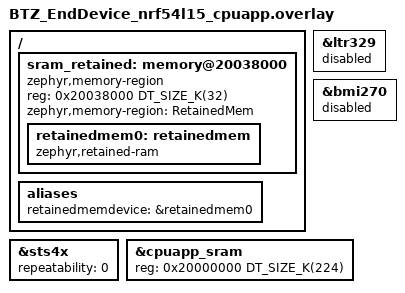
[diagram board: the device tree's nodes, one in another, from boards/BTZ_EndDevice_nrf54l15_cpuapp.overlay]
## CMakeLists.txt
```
cmake_minimum_required(VERSION 3.20.0)

find_package(Zephyr REQUIRED HINTS $ENV{ZEPHYR_BASE})
project(lpn_off)

target_sources(app PRIVATE
  src/main.c
  src/model_handler.c
  src/retained.c
)

zephyr_library_include_directories(.)
# net.h stosu mesh - stad bt_mesh.seq, ktore odtwarzamy po System OFF
zephyr_library_include_directories(${ZEPHYR_BASE}/subsys/bluetooth/mesh)
```

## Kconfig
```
# Parametry aplikacji LPN OFF sterowane flaga builda (-DCONFIG_...=...).
# Nazwy zgodne z apps/lpn i apps/lpn_mock - ta sama flaga dziala we wszystkich.

config LPN_SENSOR_INTERVAL_S
	int "Interwal odczytu i publikacji temperatury do Frienda [s]"
	default 10
	range 1 86400
	help
	  Odstep miedzy kolejnymi publikacjami Sensor Server -> Friend.
	  Sterowane build-time: -DCONFIG_LPN_SENSOR_INTERVAL_S=<sekundy>.

	  Tu jest to jednoczesnie czas spedzony w System OFF: wezel budzi sie,
	  publikuje i znowu odcina zasilanie. Pobudke daje GRTC taktowany z LFXO.

config LPN_PROV_TIMEOUT_S
	int "Limit czasu na provisioning i konfiguracje od Frienda [s]"
	default 60
	range 5 600
	help
	  Dotyczy tylko zimnego startu. Po przekroczeniu wezel i tak idzie w
	  System OFF, zeby pomiar nie zawisl.

config LPN_CFG_SETTLE_MS
	int "Zapas po wykryciu konca konfiguracji, przed wejsciem w tryb LPN [ms]"
	default 8000
	range 0 30000
	help
	  Dotyczy tylko zimnego startu. Znacznikiem konca konfiguracji jest
	  ustawiony adres publikacji, czyli ostatni krok Frienda (mod_pub_set) -
	  ten zapas pokrywa tylko retransmisje Frienda po zgubionym Status.

	  Caly ten czas LPN jest zwyklym wezlem mesh, wiec skanuje bez przerwy
	  (~4-5 mA). Do pomiarow energii warto zejsc do 500-1000 ms:
	  -DCONFIG_LPN_CFG_SETTLE_MS=1000.

config LPN_FRIENDSHIP
	bool "Nawiazuj friendship przed publikacja"
	default y
	help
	  Wylacz, zeby zmierzyc cykl bez kosztu Friend Request (okno na oferty
	  to ~1,1 s ciaglego RX). Publikacja dziala bez friendship - to tylko TX.

config LPN_FRIENDSHIP_TIMEOUT_S
	int "Limit czasu na nawiazanie friendship [s]"
	default 20
	range 1 120
	help
	  Bez "depends on LPN_FRIENDSHIP" swiadomie: main.c bramkuje uzycie
	  zwyklym if-em na IS_ENABLED(), a nie #if, wiec ten symbol musi istniec
	  takze przy LPN_FRIENDSHIP=n - inaczej build nie linkuje sie na
	  niezdefiniowanym CONFIG_LPN_FRIENDSHIP_TIMEOUT_S.

config LPN_DRAIN_MS
	int "Zwloka po publikacji, zeby reklama wyszla w eter [ms]"
	default 500
	range 0 5000
	help
	  System OFF ucina nadawanie w polowie, wiec trzeba dac adverowi czas.

config LPN_SEQ_MARGIN
	int "Zapas doliczany do odtworzonego licznika seq"
	default 32
	range 0 4096
	help
	  Pokrywa wiadomosci, ktore mogly wyjsc po zapisie bloku retencyjnego.
	  Bez zapasu Friend moglby odrzucic nas na replay protection.

source "Kconfig.zephyr"
```

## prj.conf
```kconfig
# Wariant do POMIARU ENERGII: pelny cykl LPN, potem System OFF z pobudka z GRTC.
# Czujnik REALNY (STS4X). Wersja z retencja RAM: -DEXTRA_CONF_FILE=overlay-ret.conf

# Logi i konsola: WYLACZONE (UART i watek logow pobieraja prad)
CONFIG_LOG=n
CONFIG_SERIAL=n
CONFIG_CONSOLE=n
CONFIG_UART_CONSOLE=n
# Board defconfig wymusza RTT_CONSOLE=y - gasimy jawnie (jak w apps/baseline).
CONFIG_RTT_CONSOLE=n
# Potrzebne tylko do drukowania floatow w logach (bt_mesh_sensor_ch_str).
CONFIG_CBPRINTF_FP_SUPPORT=n

# BLE
CONFIG_BT=y
CONFIG_BT_DEVICE_NAME="LPN Off"
CONFIG_BT_OBSERVER=y
CONFIG_BT_BROADCASTER=y

# Mesh: provisioning REALNY - adres i klucze przychodza od Frienda
CONFIG_BT_MESH=y
CONFIG_BT_MESH_PB_ADV=y

# Rola LPN
CONFIG_BT_MESH_LOW_POWER=y
# 600 x 100 ms = 60 s; ta sama wartosc co w apps/lpn, zeby pomiary byly porownywalne.
CONFIG_BT_MESH_LPN_POLL_TIMEOUT=600
CONFIG_BT_MESH_LPN_RETRY_TIMEOUT=3
# Opoznienie Friend Offer liczy Friend jako
# MAX(RECV_WIN_FACTOR * FRIEND_RECV_WIN - RSSI_FACTOR * rssi, 100) ms.
# Przy FRIEND_RECV_WIN=50 i faktorze 1.0 wychodzi ~100 ms, a LPN z
# LPN_ESTABLISHMENT=y ma w tym momencie scanner JESZCZE wylaczony
# (FRIEND_REQ_WAIT = 100 ms w lpn.c). Oferta leci jednym adverem, wiec
# przepada, a kolejna proba to 1,1 s okna + 3 s retry. Faktor 2.0 przesuwa
# oferte na ~140-160 ms, czyli w srodek okna skanowania LPN-a.
# Nie kosztuje energii: LPN i tak skanuje przez cale okno ofert.
CONFIG_BT_MESH_LPN_RECV_WIN_FACTOR=2
# ODWROTNIE niz w apps/lpn: tu friendship nawiazujemy w KAZDYM cyklu, wiec
# zredukowany duty cycle skanowania (domyslne =y) oplaca sie kilkukrotnie.
# Przy =n radio skanuje bez przerwy przez cale okno ofert i przez kazda 3 s przerwe retry.
CONFIG_BT_MESH_LPN_ESTABLISHMENT=y
# Auto-LPN OFF: w tryb LPN wchodzimy recznie, po konfiguracji (patrz main.c).
CONFIG_BT_MESH_LPN_AUTO=n

# Funkcje wymagajace ciagle wlaczonego radia - zbedne dla LPN
CONFIG_BT_MESH_RELAY=n
CONFIG_BT_MESH_FRIEND=n
CONFIG_BT_MESH_BEACON_ENABLED=n
CONFIG_BT_MESH_GATT_PROXY_ENABLED=n

# Sensor Server: jeden czujnik (temperatura z STS4X)
CONFIG_BT_MESH_SENSOR_SRV=y
CONFIG_BT_MESH_SENSOR_SRV_SENSORS_MAX=1

# Wezel BEZSTANOWY: po restarcie Friend prowizjonuje go od nowa
CONFIG_BT_SETTINGS=n
# Settings/flash zostaja: bez nich blad linkera storage_*_object (PSA ITS na nRF54L).
CONFIG_SETTINGS=y
CONFIG_FLASH=y
CONFIG_FLASH_MAP=y

# System OFF z pobudka z GRTC - GRTC leci z LFXO, wiec odlicza takze w OFF
CONFIG_POWEROFF=y
CONFIG_REBOOT=y
# Rozpoznanie, czy to zimny start czy pobudka z OFF (RESET_CLOCK)
CONFIG_HWINFO=y

# Blok retencyjny: sterownik jest w OBU wariantach, zeby mapa pamieci byla ta sama.
# Sama retencje w System OFF wlacza dopiero RETAINED_MEM_NRF_RAM_CTRL.
CONFIG_RETAINED_MEM=y
CONFIG_RETAINED_MEM_ZEPHYR_RAM=y
CONFIG_RETAINED_MEM_NRF_RAM_CTRL=n
CONFIG_CRC=y

# Stosy i bufory
CONFIG_MAIN_STACK_SIZE=4400
CONFIG_MAIN_THREAD_PRIORITY=-2
CONFIG_SYSTEM_WORKQUEUE_STACK_SIZE=4800
CONFIG_BT_MESH_RX_SEG_MAX=32
CONFIG_BT_MESH_TX_SEG_MSG_COUNT=3
# Wiecej buforow adv: wezel odbiera segmenty i jednoczesnie odsyla ACK.
CONFIG_BT_MESH_ADV_BUF_COUNT=16

# SAR RX: prog 1, bo AppKey Add ma 2 segmenty a ACK retransmituje sie gdy > prog
CONFIG_BT_MESH_SAR_RX_SEG_THRESHOLD=0x01
# ACK wysylany 4x - pojedynczy zgubiony ACK konczyl konfiguracje bledem -116.
CONFIG_BT_MESH_SAR_RX_ACK_RETRANS_COUNT=0x03
# Dluzszy discard: niekompletny SDU przezywa okno retransmisji Frienda.
CONFIG_BT_MESH_SAR_RX_DISCARD_TIMEOUT=0x0a
# NETWORK_TRANSMIT zostaje DOMYSLNY - podnoszenie go opoznialo ACK i zapychalo adv.

# --- Niezawodnosc provisioningu (PB-ADV) ---
# Domyslnie PDU danych provisioningu leca POJEDYNCZO (retrans=0) - tylko ACK i
# Link Close maja 2 powtorzenia. Na granicznym linku gubi sie ich dosc, ze
# wymiana nie domyka sie przed watchdogiem Frienda. 7 = kazde PDU nadane 8x.
CONFIG_BT_MESH_PB_ADV_TRANS_PDU_RETRANSMIT_COUNT=7
# Beacon nieprovisionowanego co 1 s zamiast co 5 s - Friend znajduje nas szybciej.
CONFIG_BT_MESH_UNPROV_BEACON_INT=1
# Pelna moc nadawania. Domyslne 0 dBm nie wyrabialo na 5 m.
CONFIG_BT_CTLR_TX_PWR_ANTENNA=8

# --- Opcjonalny lewar energetyczny (odkomentuj i zmierz) ---
# Publikacja idzie 1x zamiast 3x. Dotyczy tylko Sensor Status - Friend Request
# i Friend Poll i tak leca pojedynczo (POLL_XMIT w lpn.c).
#CONFIG_BT_MESH_NETWORK_TRANSMIT_COUNT=0
```

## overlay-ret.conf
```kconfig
# Wariant Z RETENCJA RAM: sekcja retencyjna przezywa System OFF.
# Jedyna roznica wobec prj.conf - reszta konfiguracji i mapa pamieci sa te same.
CONFIG_RETAINED_MEM_NRF_RAM_CTRL=y
```

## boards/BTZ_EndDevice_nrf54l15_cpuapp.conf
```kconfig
CONFIG_ZMS=y
CONFIG_SETTINGS_ZMS_CUSTOM_SECTOR_COUNT=y
CONFIG_SETTINGS_ZMS_SECTOR_COUNT=8
CONFIG_ZMS_LOOKUP_CACHE=y
CONFIG_ZMS_LOOKUP_CACHE_SIZE=512
CONFIG_ZMS_LOOKUP_CACHE_FOR_SETTINGS=y

CONFIG_I2C=y
CONFIG_REGULATOR=y
CONFIG_REGULATOR_FIXED=y
CONFIG_SENSOR=y
```

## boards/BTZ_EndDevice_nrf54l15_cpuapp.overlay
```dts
/*
 * Wylaczamy nieuzywane czujniki, zeby zdjac ten narzut energetyczny.
 */

&ltr329 {
	status = "disabled";
};

&bmi270 {
	status = "disabled";
};

/*
 * STS4X: tryb pomiaru "low"
 */
&sts4x {
	repeatability = <0>;
};

/*
 * Region retencyjny na ostatniej sekcji RAM. Granulacja retencji na nRF54L15
 * to 32 kB (RAM_SECTION_UNIT_SIZE), wiec mniejszy region i tak podtrzymalby
 * cala sekcje - trzymamy wiec pelne 32 kB, zeby koszt byl jawny.
 * Region jest w OBU wariantach builda; retencje wlacza dopiero Kconfig.
 */
/ {
	sram_retained: memory@20038000 {
		compatible = "zephyr,memory-region", "mmio-sram";
		reg = <0x20038000 DT_SIZE_K(32)>;
		zephyr,memory-region = "RetainedMem";
		status = "okay";

		retainedmem0: retainedmem {
			compatible = "zephyr,retained-ram";
			status = "okay";
		};
	};

	aliases {
		retainedmemdevice = &retainedmem0;
	};
};

/* SRAM skrocony do 224 kB, zeby nie nachodzil na region retencyjny */
&cpuapp_sram {
	reg = <0x20000000 DT_SIZE_K(224)>;
	ranges = <0x0 0x20000000 0x38000>;
};
```

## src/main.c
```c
#include <bluetooth/mesh/models.h>
#include <stdint.h>
#include <zephyr/bluetooth/bluetooth.h>
#include <zephyr/bluetooth/mesh.h>
#include <zephyr/drivers/hwinfo.h>
#include <zephyr/drivers/timer/nrf_grtc_timer.h>
#include <zephyr/kernel.h>
#include <zephyr/logging/log.h>
#include <zephyr/sys/poweroff.h>
#include <zephyr/sys/reboot.h>

#include "model_handler.h"
#include "retained.h"

/* Wewnetrzny stan sieci mesh - stad bierzemy i odtwarzamy licznik seq */
#include "net.h"

LOG_MODULE_REGISTER(lpn_off, LOG_LEVEL_INF);

/* Adresacja i klucze - musza zgadzac sie z apps/friend */
#define NET_IDX     0x0000
#define APP_IDX     0x0000
#define FRIEND_ADDR 0x0001

static const uint8_t net_key[16] = {
    0x00, 0x11, 0x22, 0x33, 0x44, 0x55, 0x66, 0x77, 0x88, 0x99, 0xaa, 0xbb, 0xcc, 0xdd, 0xee, 0xff,
};
static const uint8_t app_key[16] = {
    0xff, 0xee, 0xdd, 0xcc, 0xbb, 0xaa, 0x99, 0x88, 0x77, 0x66, 0x55, 0x44, 0x33, 0x22, 0x11, 0x00,
};
/* DevKey po cieplym starcie - Friend nie wysyla juz Configa, wiec moze byc staly */
static const uint8_t lpn_dev_key[16] = {
    0xb0, 0xb1, 0xb2, 0xb3, 0xb4, 0xb5, 0xb6, 0xb7, 0xb8, 0xb9, 0xba, 0xbb, 0xbc, 0xbd, 0xbe, 0xbf,
};

/* UUID w unprovisioned beacon - Friend provisionuje tylko ten wezel */
static const uint8_t dev_uuid[16] = {0x1b, 0x7a, 0x0c, 0x54};

/* Interwal publikacji temperatury - tu zarazem czas w System OFF (patrz Kconfig) */
#ifndef CONFIG_LPN_SENSOR_INTERVAL_S
#define CONFIG_LPN_SENSOR_INTERVAL_S 10
#endif

/* Co ile pytac, czy Friend domknal konfiguracje */
#define CFG_POLL_INTERVAL K_MSEC(200)
/* Zapas na retry Frienda po zgubionym Status (patrz Kconfig) */
#define CFG_SETTLE_DELAY K_MSEC(CONFIG_LPN_CFG_SETTLE_MS)

static K_SEM_DEFINE(sem_provisioned, 0, 1);
static K_SEM_DEFINE(sem_friendship, 0, 1);

/* Provisioning zakonczony - wezel ma adres i klucze, czekamy na konfiguracje */
static void prov_complete(uint16_t net_idx, uint16_t addr)
{
    LOG_INF("Sprovisionowany przez Frienda - adres 0x%04x", addr);

    retained.addr = addr;
    k_sem_give(&sem_provisioned);
}

static const struct bt_mesh_prov prov = {
    .uuid = dev_uuid,
    .complete = prov_complete,
};

/* Callbacki LPN */
static void lpn_established(uint16_t net_idx, uint16_t friend_addr, uint8_t queue_size,
                            uint8_t recv_window)
{
    LOG_INF("Friendship nawiazany z Friendem 0x%04x (queue %u, recv_window %u ms)", friend_addr,
            queue_size, recv_window);

    k_sem_give(&sem_friendship);
}

static void lpn_terminated(uint16_t net_idx, uint16_t friend_addr)
{
    LOG_WRN("Friendship zerwany z Friendem 0x%04x", friend_addr);
}

BT_MESH_LPN_CB_DEFINE(lpn_cb) = {
    .established = lpn_established,
    .terminated = lpn_terminated,
};

/* Odklada stan do retencji i odcina zasilanie; GRTC (z LFXO) budzi nas z OFF */
static void enter_system_off(void)
{
    /* seq musi rosnac monotonicznie, inaczej Friend odrzuci nas na replay protection */
    retained.iv_index = bt_mesh.iv_index;
    retained.seq = bt_mesh.seq;
    retained.cycles++;
    retained_save();

    int err = z_nrf_grtc_wakeup_prepare((uint64_t)CONFIG_LPN_SENSOR_INTERVAL_S * USEC_PER_SEC);

    if (err) {
        /* Bez uzbrojonej pobudki System OFF bylby wieczny - lepiej sie zrestartowac */
        LOG_ERR("Uzbrojenie pobudki GRTC nieudane (err %d) - restart", err);
        k_sleep(K_SECONDS(CONFIG_LPN_SENSOR_INTERVAL_S));
        sys_reboot(SYS_REBOOT_COLD);
    }

    LOG_INF("System OFF na %d s (cykl %u)", CONFIG_LPN_SENSOR_INTERVAL_S, retained.cycles);
    sys_poweroff();
}

/* Sciezka zimnego startu: pelny provisioning i konfiguracja od Frienda */
static int join_network_cold(void)
{
    int err = bt_mesh_prov_enable(BT_MESH_PROV_ADV);

    if (err) {
        LOG_ERR("Wlaczenie provisioningu (beacon) nieudane (err %d)", err);
        return err;
    }

    LOG_INF("Czekam na provisioning od Frienda...");
    err = k_sem_take(&sem_provisioned, K_SECONDS(CONFIG_LPN_PROV_TIMEOUT_S));
    if (err) {
        LOG_ERR("Provisioning nie doszedl do skutku w %d s", CONFIG_LPN_PROV_TIMEOUT_S);
        return err;
    }

    /* Adres publikacji ustawia ostatni krok konfiguracji - to nasz znacznik konca */
    for (int i = 0; i < CONFIG_LPN_PROV_TIMEOUT_S * 5; i++) {
        if (model_handler_is_configured()) {
            LOG_INF("Konfiguracja zakonczona (publikacja ustawiona)");
            k_sleep(CFG_SETTLE_DELAY);
            retained.provisioned = 1;
            return 0;
        }
        k_sleep(CFG_POLL_INTERVAL);
    }

    LOG_ERR("Friend nie domknal konfiguracji");
    return -ETIMEDOUT;
}

/* Sciezka cieplego startu: siec i konfiguracja odtworzone z retencji, bez radia */
static int join_network_warm(void)
{
    int err = bt_mesh_provision(net_key, NET_IDX, 0, retained.iv_index, retained.addr, lpn_dev_key);

    if (err) {
        LOG_ERR("Odtworzenie provisioningu nieudane (err %d)", err);
        return err;
    }

    /* Kontynuuj licznik seq z zapasem na cokolwiek, co wyszlo po ostatnim zapisie */
    bt_mesh.seq = retained.seq + CONFIG_LPN_SEQ_MARGIN;

    err = model_handler_restore_config(NET_IDX, APP_IDX, app_key, FRIEND_ADDR);
    if (err) {
        return err;
    }

    LOG_INF("Siec odtworzona z retencji - adres 0x%04x, seq %u", retained.addr, bt_mesh.seq);
    return 0;
}

int main(void)
{
    uint32_t reset_cause = 0;
    int err;

    (void)hwinfo_get_reset_cause(&reset_cause);
    (void)hwinfo_clear_reset_cause();

    /* Waznosc bloku retencyjnego rozstrzyga, ktora sciezka startu nas czeka */
    bool warm = retained_load();

    LOG_INF("Start lpn_off: %s (cykl %u, reset 0x%08x)",
            warm ? "cieply start z retencji RAM" : "zimny start", retained.cycles, reset_cause);

    err = bt_enable(NULL);
    if (err) {
        LOG_ERR("bt_enable nieudany (err %d)", err);
        enter_system_off();
    }

    err = bt_mesh_init(&prov, model_handler_init());
    if (err) {
        LOG_ERR("Inicjalizacja mesh nieudana (err %d)", err);
        enter_system_off();
    }

    if (warm && retained.provisioned) {
        err = join_network_warm();
    }
    else {
        err = join_network_cold();
    }

    if (err) {
        /* Nie udalo sie wejsc do sieci - i tak zasnij, zeby pomiar szedl dalej */
        enter_system_off();
    }

    if (IS_ENABLED(CONFIG_LPN_FRIENDSHIP)) {
        err = bt_mesh_lpn_set(true);
        if (err) {
            LOG_ERR("Wlaczenie LPN nieudane (err %d)", err);
        }
        else if (k_sem_take(&sem_friendship, K_SECONDS(CONFIG_LPN_FRIENDSHIP_TIMEOUT_S))) {
            LOG_WRN("Brak Frienda w %d s - publikuje bez friendship",
                    CONFIG_LPN_FRIENDSHIP_TIMEOUT_S);
        }
    }

    /* Jedyna rzecz, po ktora sie budzimy */
    err = model_handler_publish_temp();
    if (err) {
        LOG_WRN("Publikacja nieudana (err %d)", err);
    }

    /* Reklama musi zdazyc wyjsc w eter przed odcieciem zasilania */
    k_sleep(K_MSEC(CONFIG_LPN_DRAIN_MS));

    enter_system_off();

    return 0;
}
```

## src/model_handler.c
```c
#include "model_handler.h"

#include <bluetooth/mesh/models.h>
#include <zephyr/bluetooth/bluetooth.h>
#include <zephyr/bluetooth/mesh.h>
#include <zephyr/device.h>
#include <zephyr/drivers/regulator.h>
#include <zephyr/drivers/sensor.h>
#include <zephyr/kernel.h>
#include <zephyr/logging/log.h>

LOG_MODULE_DECLARE(lpn_off);

/* Health Server */
static const struct bt_mesh_health_srv_cb health_srv_cb; /* puste callbacki */
static struct bt_mesh_health_srv health_srv = {
    .cb = &health_srv_cb,
};

BT_MESH_HEALTH_PUB_DEFINE(health_pub, 0);

/* Sensor Server (temperatura STS4X) */
static const struct device *const sensor_dev = DEVICE_DT_GET(DT_NODELABEL(sts4x));

/* Bramka zasilania czujnika - wlaczana tylko na czas pomiaru */
static const struct device *const sensor_pwr = DEVICE_DT_GET(DT_NODELABEL(sensor_pwr));
static bool sensor_pwr_ready;

/* Czas na power-up szyny i reset STS4X przed pomiarem */
#define STS4X_POWERUP_MS 2

/* Odczyt z STS4X i zakodowanie do formatu wartosci czujnika mesh */
static int temp_sample(struct bt_mesh_sensor_value *rsp)
{
    struct sensor_value val;
    int err;

    /* Zasilamy szyne czujnika tylko na czas odczytu */
    if (sensor_pwr_ready) {
        err = regulator_enable(sensor_pwr);
        if (err) {
            LOG_ERR("Zalaczenie sensor_pwr nieudane (err %d)", err);
            return err;
        }
        k_msleep(STS4X_POWERUP_MS); /* power-up rail + reset STS4X */
    }

    err = sensor_sample_fetch(sensor_dev);
    if (err) {
        LOG_ERR("sensor_sample_fetch nieudany (err %d)", err);
        goto power_off;
    }

    err = sensor_channel_get(sensor_dev, SENSOR_CHAN_AMBIENT_TEMP, &val);
    if (err) {
        LOG_ERR("sensor_channel_get nieudany (err %d)", err);
        goto power_off;
    }

    /* Konwersja wartosci czujnika do formatu mesh */
    err = bt_mesh_sensor_value_from_sensor_value(bt_mesh_sensor_present_amb_temp.channels[0].format,
                                                 &val, rsp);
    if (err == -ERANGE) {
        err = 0; /* -ERANGE = przycieto do zakresu, OK */
    }
    else if (err) {
        LOG_ERR("Kodowanie wartosci nieudane (err %d)", err);
    }

power_off:
    /* Odetnij zasilanie czujnika */
    if (sensor_pwr_ready) {
        int derr = regulator_disable(sensor_pwr);
        if (derr) {
            LOG_ERR("Wylaczenie sensor_pwr nieudane (err %d)", derr);
        }
    }

    return err;
}

/* Callback modelu: wolany, gdy klient wysle Sensor Get */
static int temp_get(struct bt_mesh_sensor_srv *srv, struct bt_mesh_sensor *sensor,
                    struct bt_mesh_msg_ctx *ctx, struct bt_mesh_sensor_value *rsp)
{
    int err = temp_sample(rsp);

    if (!err) {
        LOG_INF("Sensor Get -> temperatura: %s C", bt_mesh_sensor_ch_str(rsp));
    }
    return err;
}

static struct bt_mesh_sensor temp_sensor = {
    .type = &bt_mesh_sensor_present_amb_temp,
    .get = temp_get,
};

static struct bt_mesh_sensor *const sensors[] = {
    &temp_sensor,
};

static struct bt_mesh_sensor_srv sensor_srv = BT_MESH_SENSOR_SRV_INIT(sensors, ARRAY_SIZE(sensors));

/* Kompozycja wezla */
static const struct bt_mesh_elem elements[] = {
    BT_MESH_ELEM(0,
                 BT_MESH_MODEL_LIST(BT_MESH_MODEL_CFG_SRV,
                                    BT_MESH_MODEL_HEALTH_SRV(&health_srv, &health_pub),
                                    BT_MESH_MODEL_SENSOR_SRV(&sensor_srv)),
                 BT_MESH_MODEL_NONE),
};

static const struct bt_mesh_comp comp = {
    .cid = BT_COMP_ID_LF,
    .elem = elements,
    .elem_count = ARRAY_SIZE(elements),
};

int model_handler_publish_temp(void)
{
    struct bt_mesh_sensor_value val;
    int err;

    err = temp_sample(&val);
    if (err) {
        return err;
    }

    LOG_INF("Temperatura: %s C", bt_mesh_sensor_ch_str(&val));

    /* Publikacja wartosci czujnika do Frienda */
    err = bt_mesh_sensor_srv_pub(&sensor_srv, NULL, &temp_sensor, &val);
    if (err) {
        LOG_DBG("Publikacja pominieta (err %d) - brak adresu publikacji?", err);
    }

    return err;
}

bool model_handler_is_configured(void)
{
    /* Adres publikacji ustawia ostatni krok konfiguracji Frienda (mod_pub_set) */
    return sensor_srv.pub.addr != BT_MESH_ADDR_UNASSIGNED;
}

int model_handler_restore_config(uint16_t net_idx, uint16_t app_idx, const uint8_t app_key[16],
                                 uint16_t pub_addr)
{
    /* Po cieplym starcie Friend nie widzi beacona, wiec Config Client nie ruszy */
    uint8_t status = bt_mesh_app_key_add(app_idx, net_idx, app_key);

    if (status) {
        LOG_ERR("AppKey add nieudany (status 0x%02x)", status);
        return -EIO;
    }

    /* Rownowaznik mod_app_bind - bez tego publikacja nie ma czym szyfrowac */
    const struct bt_mesh_model *mod = bt_mesh_model_find(&elements[0], BT_MESH_MODEL_ID_SENSOR_SRV);

    if (!mod) {
        LOG_ERR("Nie znaleziono modelu Sensor Server");
        return -ENODEV;
    }
    mod->keys[0] = app_idx;

    /* Rownowaznik mod_pub_set - te same parametry, co ustawia Friend */
    sensor_srv.pub.addr = pub_addr;
    sensor_srv.pub.key = app_idx;
    sensor_srv.pub.ttl = 7;
    sensor_srv.pub.period = 0;
    sensor_srv.pub.retransmit = BT_MESH_TRANSMIT(0, 30);

    LOG_INF("Konfiguracja odtworzona lokalnie - publikacja na 0x%04x", pub_addr);

    return 0;
}

const struct bt_mesh_comp *model_handler_init(void)
{
    if (!device_is_ready(sensor_dev)) {
        LOG_ERR("STS4X niegotowy - Sensor Server nie bedzie mial danych");
    }

    /* Po inicjalizacji zostawiamy czujnik bez zasilania */
    sensor_pwr_ready = device_is_ready(sensor_pwr);
    if (sensor_pwr_ready) {
        int err = regulator_disable(sensor_pwr);
        if (err) {
            LOG_ERR("Wylaczenie sensor_pwr po init nieudane (err %d)", err);
        }
        else {
            LOG_INF("sensor_pwr OFF - budzony tylko na czas odczytu STS4X");
        }
    }
    else {
        LOG_WRN("sensor_pwr niegotowy - szyna zostanie na stale");
    }

    return &comp;
}
```

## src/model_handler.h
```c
#ifndef MODEL_HANDLER_H__
#define MODEL_HANDLER_H__

#include <zephyr/bluetooth/mesh.h>

#ifdef __cplusplus
extern "C" {
#endif

/* Inicjuje modele mesh wezla i zwraca kompozycje */
const struct bt_mesh_comp *model_handler_init(void);

/* Odczytuje temperature z STS4X i publikuje ja przez Sensor Server */
int model_handler_publish_temp(void);

/* Czy Friend skonczyl konfiguracje - decyduje, kiedy mozna przejsc w tryb LPN */
bool model_handler_is_configured(void);

/* Odtwarza konfiguracje lokalnie, zamiast czekac na Config Client Frienda */
int model_handler_restore_config(uint16_t net_idx, uint16_t app_idx, const uint8_t app_key[16],
                                 uint16_t pub_addr);

#ifdef __cplusplus
}
#endif

#endif /* MODEL_HANDLER_H__ */
```

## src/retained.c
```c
#include "retained.h"

#include <stddef.h>
#include <string.h>
#include <zephyr/device.h>
#include <zephyr/devicetree.h>
#include <zephyr/drivers/retained_mem.h>
#include <zephyr/logging/log.h>
#include <zephyr/sys/byteorder.h>
#include <zephyr/sys/crc.h>

LOG_MODULE_DECLARE(lpn_off);

/* "LPNO" - druga (po CRC) bariera przed przypadkowymi smieciami w RAM */
#define RETAINED_MAGIC 0x4c504e4f

static const struct device *const retained_dev = DEVICE_DT_GET(DT_ALIAS(retainedmemdevice));

struct retained_data retained;

/* CRC liczone po wszystkim, co lezy przed polem crc */
#define RETAINED_CRC_OFFSET   offsetof(struct retained_data, crc)
#define RETAINED_CHECKED_SIZE (RETAINED_CRC_OFFSET + sizeof(retained.crc))

bool retained_load(void)
{
    if (!device_is_ready(retained_dev)) {
        LOG_ERR("Urzadzenie retencyjne niegotowe");
        memset(&retained, 0, sizeof(retained));
        return false;
    }

    int err = retained_mem_read(retained_dev, 0, (uint8_t *)&retained, sizeof(retained));
    if (err) {
        LOG_ERR("Odczyt bloku retencyjnego nieudany (err %d)", err);
        memset(&retained, 0, sizeof(retained));
        return false;
    }

    /* Reszta CRC-32/ISO-HDLC liczonego po wiadomosci z doklejonym CRC */
    const uint32_t residue = 0x2144df1c;
    bool valid = (crc32_ieee((const uint8_t *)&retained, RETAINED_CHECKED_SIZE) == residue) &&
                 (retained.magic == RETAINED_MAGIC);

    if (!valid) {
        /* Zimny start albo retencja wylaczona - startujemy od zera */
        memset(&retained, 0, sizeof(retained));
    }

    return valid;
}

void retained_save(void)
{
    if (!device_is_ready(retained_dev)) {
        return;
    }

    retained.magic = RETAINED_MAGIC;
    retained.crc = sys_cpu_to_le32(crc32_ieee((const uint8_t *)&retained, RETAINED_CRC_OFFSET));

    int err = retained_mem_write(retained_dev, 0, (const uint8_t *)&retained, sizeof(retained));
    if (err) {
        LOG_ERR("Zapis bloku retencyjnego nieudany (err %d)", err);
    }
}
```

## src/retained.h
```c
#ifndef RETAINED_H__
#define RETAINED_H__

#include <stdbool.h>
#include <stdint.h>

/* Stan mesh przenoszony przez System OFF w podtrzymanej sekcji RAM */
struct retained_data {
    uint32_t magic;      /* znacznik formatu - odsiewa smieci po zimnym starcie */
    uint32_t cycles;     /* licznik cykli pomiarowych od zimnego startu */
    uint32_t iv_index;   /* IV Index sieci */
    uint32_t seq;        /* nastepny seq do wyslania - musi rosnac monotonicznie */
    uint16_t addr;       /* adres unicast przydzielony przez Frienda */
    uint8_t provisioned; /* 1 = mamy komplet danych do odtworzenia sieci */
    uint8_t reserved;    /* wyrownanie */
    uint32_t crc;        /* CRC32 wszystkiego przed soba - musi byc ostatnie */
};

extern struct retained_data retained;

/* Wczytuje blok retencyjny; false = brak sprzetowej retencji albo zle CRC */
bool retained_load(void);

/* Zapisuje blok retencyjny wraz z nowym CRC */
void retained_save(void);

#endif /* RETAINED_H__ */
```
